# iostr910f register map
Registers are 32-bit, access not given, no defined reset value unless marked. A register's access mark holds for its fields unless they carry their own. Addresses are absolute; registers are grouped by the start of their names; [hi:lo] are bit positions; {n}, {i} and the like mark numbered series; 'fields as' and 'values as' point back to an identical list.

## TIM3
0x48005000 TIM3_IC1R_BUF 16-bit
0x48005004 TIM3_IC2R_BUF 16-bit
0x48005008 TIM3_OC1R_BUF 16-bit
0x4800500C TIM3_OC2R_BUF 16-bit
0x48005010 TIM3_CNTR_BUF 16-bit
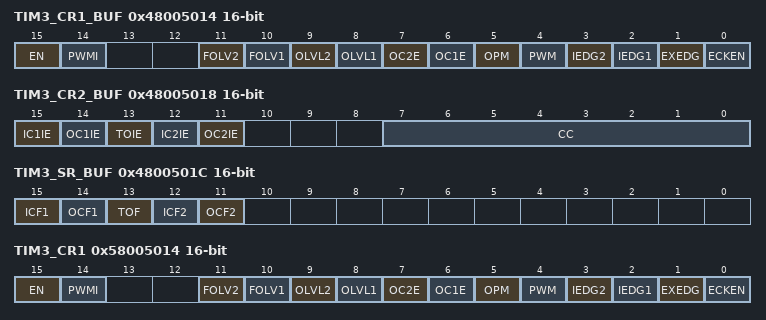
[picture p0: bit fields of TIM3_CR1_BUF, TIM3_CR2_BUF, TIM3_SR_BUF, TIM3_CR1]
0x48005014 TIM3_CR1_BUF 16-bit
  [15] EN, [14] PWMI, [11] FOLV2, [10] FOLV1, [9] OLVL2, [8] OLVL1, [7] OC2E, [6] OC1E, [5] OPM, [4] PWM, [3] IEDG2, [2] IEDG1, [1] EXEDG, [0] ECKEN
0x48005018 TIM3_CR2_BUF 16-bit
  [15] IC1IE, [14] OC1IE, [13] TOIE, [12] IC2IE, [11] OC2IE, [7:0] CC
0x4800501C TIM3_SR_BUF 16-bit
  [15] ICF1, [14] OCF1, [13] TOF, [12] ICF2, [11] OCF2
0x58005000 TIM3_IC1R 16-bit
0x58005004 TIM3_IC2R 16-bit
0x58005008 TIM3_OC1R 16-bit
0x5800500C TIM3_OC2R 16-bit
0x58005010 TIM3_CNTR 16-bit
0x58005014 TIM3_CR1 16-bit
  fields as TIM3_CR1_BUF
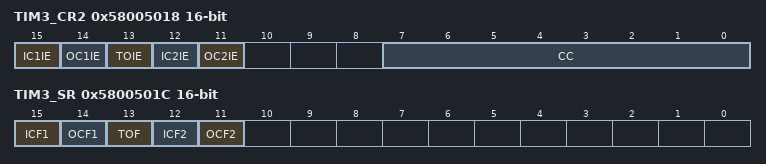
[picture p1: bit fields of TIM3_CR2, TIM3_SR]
0x58005018 TIM3_CR2 16-bit
  [15] IC1IE, [14] OC1IE, [13] TOIE, [12] IC2IE, [11] OC2IE, [7:0] CC
0x5800501C TIM3_SR 16-bit
  [15] ICF1, [14] OCF1, [13] TOF, [12] ICF2, [11] OCF2

## DMA
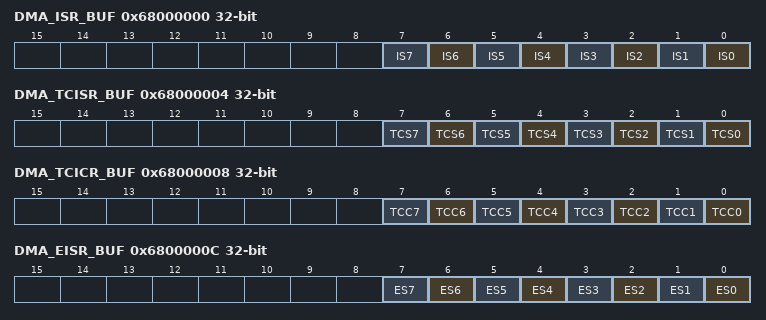
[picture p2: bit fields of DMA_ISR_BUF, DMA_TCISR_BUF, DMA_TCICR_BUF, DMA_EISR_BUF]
0x68000000 DMA_ISR_BUF
  [n] IS{n} (n=0..7)
0x68000004 DMA_TCISR_BUF
  [n] TCS{n} (n=0..7)
0x68000008 DMA_TCICR_BUF
  [n] TCC{n} (n=0..7)
0x6800000C DMA_EISR_BUF
  [n] ES{n} (n=0..7)
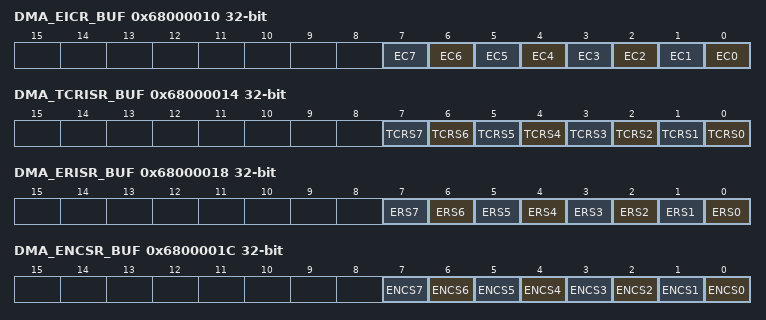
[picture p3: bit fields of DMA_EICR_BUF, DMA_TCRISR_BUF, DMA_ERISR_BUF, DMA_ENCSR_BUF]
0x68000010 DMA_EICR_BUF
  [n] EC{n} (n=0..7)
0x68000014 DMA_TCRISR_BUF
  [n] TCRS{n} (n=0..7)
0x68000018 DMA_ERISR_BUF
  [n] ERS{n} (n=0..7)
0x6800001C DMA_ENCSR_BUF
  [n] ENCS{n} (n=0..7)
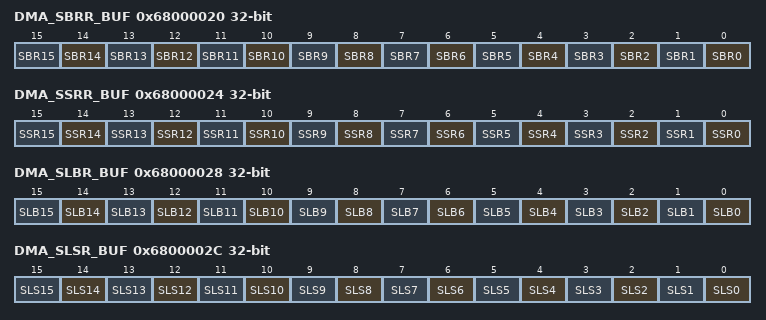
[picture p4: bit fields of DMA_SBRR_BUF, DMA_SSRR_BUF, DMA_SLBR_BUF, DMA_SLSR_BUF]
0x68000020 DMA_SBRR_BUF
  [n] SBR{n} (n=0..15)
0x68000024 DMA_SSRR_BUF
  [n] SSR{n} (n=0..15)
0x68000028 DMA_SLBR_BUF
  [n] SLB{n} (n=0..15)
0x6800002C DMA_SLSR_BUF
  [n] SLS{n} (n=0..15)
0x68000030 DMA_CNFR_BUF
  [0] EN
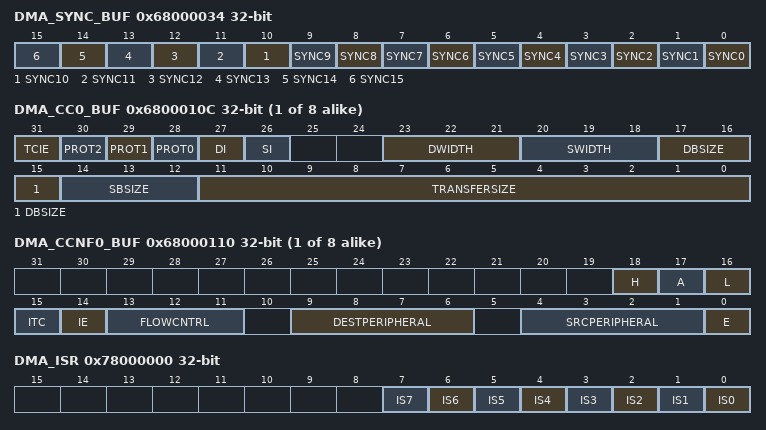
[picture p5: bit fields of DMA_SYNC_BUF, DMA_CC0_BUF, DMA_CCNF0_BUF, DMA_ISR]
0x68000034 DMA_SYNC_BUF
  [n] SYNC{n} (n=0..15)
{0x68000100+0x20*i} DMA_SRC{i}_BUF (i=0..7)
{0x68000104+0x20*i} DMA_DEST{i}_BUF (i=0..7)
{0x68000108+0x20*i} DMA_LLI{i}_BUF (i=0..7)
{0x6800010C+0x20*i} DMA_CC{i}_BUF (i=0..7)
  [31] TCIE, [30] PROT2, [29] PROT1, [28] PROT0, [27] DI, [26] SI, [23:21] DWIDTH, [20:18] SWIDTH, [17:15] DBSIZE, [14:12] SBSIZE, [11:0] TRANSFERSIZE
{0x68000110+0x20*i} DMA_CCNF{i}_BUF (i=0..7)
  [18] H, [17] A, [16] L, [15] ITC, [14] IE, [13:11] FLOWCNTRL, [9:6] DESTPERIPHERAL, [4:1] SRCPERIPHERAL, [0] E
0x78000000 DMA_ISR
  [n] IS{n} (n=0..7)
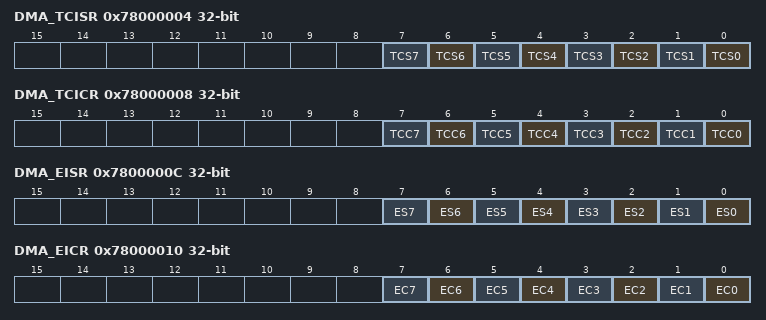
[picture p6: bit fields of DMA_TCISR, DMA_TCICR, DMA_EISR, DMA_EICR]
0x78000004 DMA_TCISR
  [n] TCS{n} (n=0..7)
0x78000008 DMA_TCICR
  [n] TCC{n} (n=0..7)
0x7800000C DMA_EISR
  [n] ES{n} (n=0..7)
0x78000010 DMA_EICR
  [n] EC{n} (n=0..7)
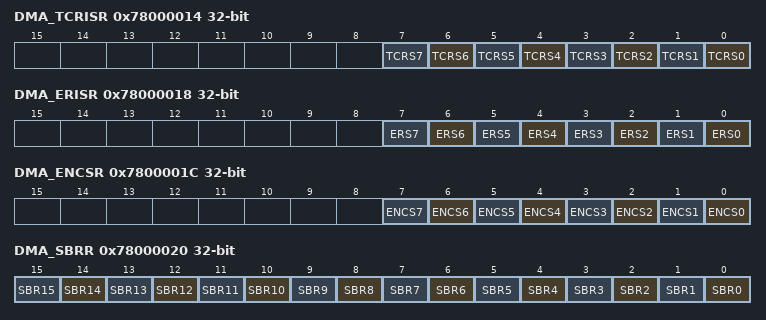
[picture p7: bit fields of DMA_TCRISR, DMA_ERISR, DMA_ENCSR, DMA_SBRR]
0x78000014 DMA_TCRISR
  [n] TCRS{n} (n=0..7)
0x78000018 DMA_ERISR
  [n] ERS{n} (n=0..7)
0x7800001C DMA_ENCSR
  [n] ENCS{n} (n=0..7)
0x78000020 DMA_SBRR
  [n] SBR{n} (n=0..15)
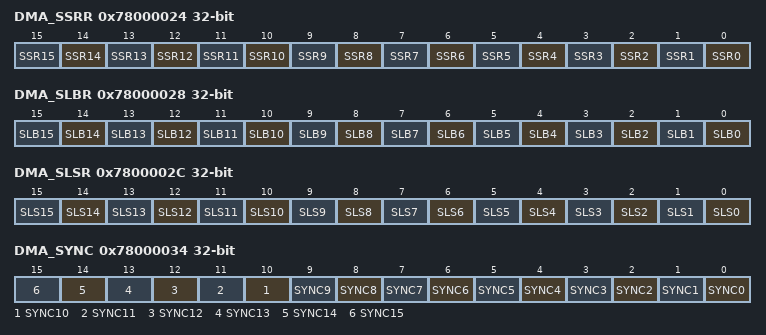
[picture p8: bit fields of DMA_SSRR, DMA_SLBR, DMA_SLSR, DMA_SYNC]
0x78000024 DMA_SSRR
  [n] SSR{n} (n=0..15)
0x78000028 DMA_SLBR
  [n] SLB{n} (n=0..15)
0x7800002C DMA_SLSR
  [n] SLS{n} (n=0..15)
0x78000030 DMA_CNFR
  [0] EN
0x78000034 DMA_SYNC
  [n] SYNC{n} (n=0..15)
{0x78000100+0x20*i} DMA_SRC{i} (i=0..7)
{0x78000104+0x20*i} DMA_DEST{i} (i=0..7)
{0x78000108+0x20*i} DMA_LLI{i} (i=0..7)
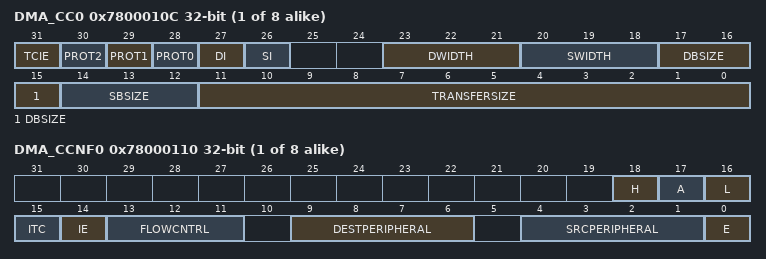
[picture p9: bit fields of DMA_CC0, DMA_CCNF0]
{0x7800010C+0x20*i} DMA_CC{i} (i=0..7)
  fields as DMA_CC0_BUF
{0x78000110+0x20*i} DMA_CCNF{i} (i=0..7)
  fields as DMA_CCNF0_BUF

## SSP0
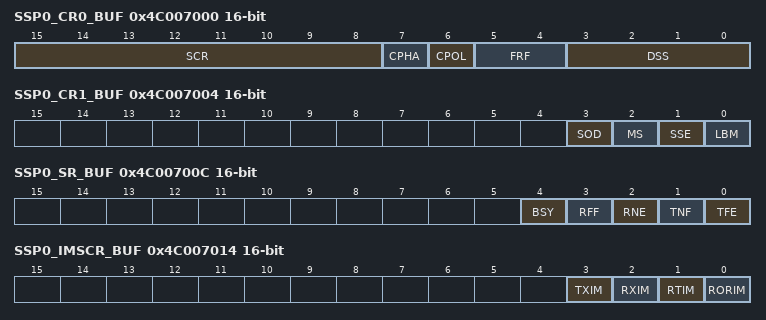
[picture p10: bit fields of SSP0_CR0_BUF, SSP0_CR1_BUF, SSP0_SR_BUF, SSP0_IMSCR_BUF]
0x4C007000 SSP0_CR0_BUF 16-bit
  [15:8] SCR, [7] CPHA, [6] CPOL, [5:4] FRF, [3:0] DSS
0x4C007004 SSP0_CR1_BUF 16-bit
  [3] SOD, [2] MS, [1] SSE, [0] LBM
0x4C007008 SSP0_DR_BUF 16-bit
0x4C00700C SSP0_SR_BUF 16-bit
  [4] BSY, [3] RFF, [2] RNE, [1] TNF, [0] TFE
0x4C007010 SSP0_PR_BUF 8-bit
0x4C007014 SSP0_IMSCR_BUF 16-bit
  [3] TXIM, [2] RXIM, [1] RTIM, [0] RORIM
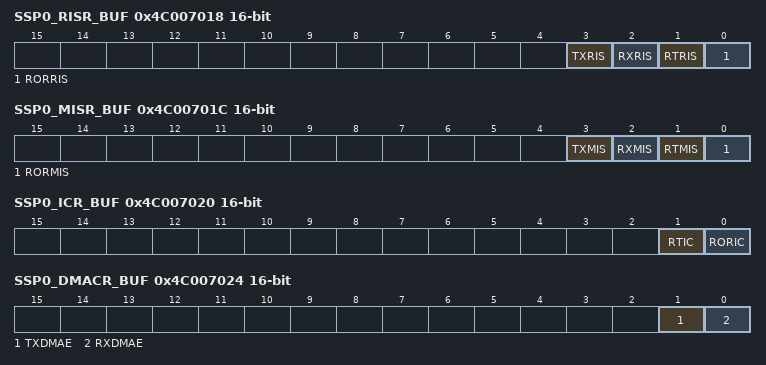
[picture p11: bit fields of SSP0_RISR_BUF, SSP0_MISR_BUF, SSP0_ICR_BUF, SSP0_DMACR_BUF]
0x4C007018 SSP0_RISR_BUF 16-bit
  [3] TXRIS, [2] RXRIS, [1] RTRIS, [0] RORRIS
0x4C00701C SSP0_MISR_BUF 16-bit
  [3] TXMIS, [2] RXMIS, [1] RTMIS, [0] RORMIS
0x4C007020 SSP0_ICR_BUF 16-bit
  [1] RTIC, [0] RORIC
0x4C007024 SSP0_DMACR_BUF 16-bit
  [1] TXDMAE, [0] RXDMAE
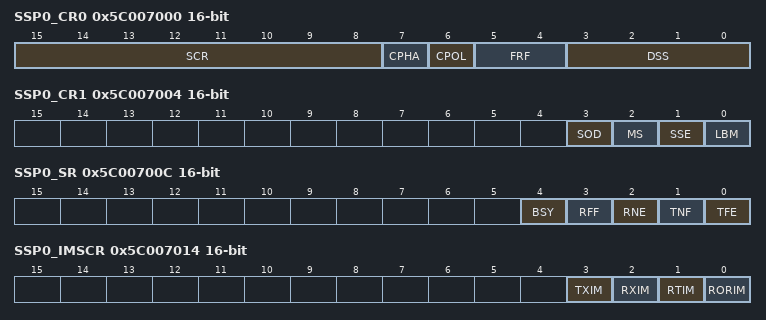
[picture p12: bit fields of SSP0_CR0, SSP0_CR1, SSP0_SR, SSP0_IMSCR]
0x5C007000 SSP0_CR0 16-bit
  [15:8] SCR, [7] CPHA, [6] CPOL, [5:4] FRF, [3:0] DSS
0x5C007004 SSP0_CR1 16-bit
  [3] SOD, [2] MS, [1] SSE, [0] LBM
0x5C007008 SSP0_DR 16-bit
0x5C00700C SSP0_SR 16-bit
  [4] BSY, [3] RFF, [2] RNE, [1] TNF, [0] TFE
0x5C007010 SSP0_PR 8-bit
0x5C007014 SSP0_IMSCR 16-bit
  [3] TXIM, [2] RXIM, [1] RTIM, [0] RORIM
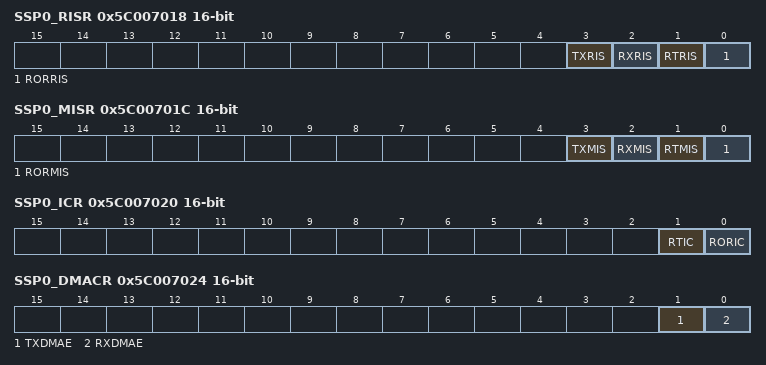
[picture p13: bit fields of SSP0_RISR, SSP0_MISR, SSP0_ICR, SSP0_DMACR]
0x5C007018 SSP0_RISR 16-bit
  [3] TXRIS, [2] RXRIS, [1] RTRIS, [0] RORRIS
0x5C00701C SSP0_MISR 16-bit
  [3] TXMIS, [2] RXMIS, [1] RTMIS, [0] RORMIS
0x5C007020 SSP0_ICR 16-bit
  [1] RTIC, [0] RORIC
0x5C007024 SSP0_DMACR 16-bit
  [1] TXDMAE, [0] RXDMAE
